# SAMA7G54D2G device description
Architecture: CORTEX-A7; Family: SAMA; Series: SAMA7G
Registers are 32-bit, read-write, reset 0x0 unless marked. A register's access mark holds for its fields unless they carry their own. Offsets are from the block's base; [hi:lo] are bit positions; lines under a group give offsets from that group; {n}, {i} and the like mark numbered series; 'fields as' and 'values as' point back to an identical list.

## I2SMCC — Inter-IC Sound Multi Channel Controller
Instances: I2SMCC0 0xE161C000, I2SMCC1 0xE1620000
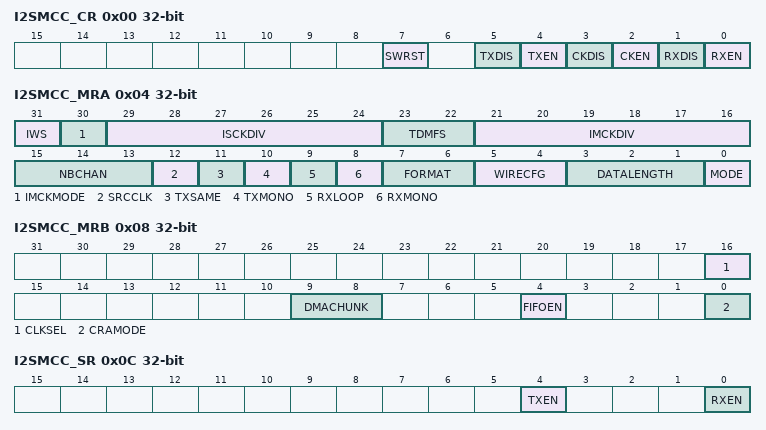
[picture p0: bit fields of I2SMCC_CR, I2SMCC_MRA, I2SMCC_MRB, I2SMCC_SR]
0x00 I2SMCC_CR wo reset not defined — Control Register
  [7] SWRST — Software Reset
    0=No effect; 1=Resets all the registers in the I2SMCC. The I2SMCC is disabled after the reset.
  [5] TXDIS — Transmitter Disable
    0=No effect; 1=Disables the I2SMCC transmitter. Bit I2SMCC_SR.TXEN is cleared when the Transmitter is stopped.
  [4] TXEN — Transmitter Enable
    0=No effect; 1=Enables the I2SMCC transmitter, if TXDIS is not '1'. Bit I2SMCC_SR.TXEN is set when the Transmitter is started.
  [3] CKDIS — Clocks Disable
    0=No effect; 1=Disables the I2SMCC clock generation
  [2] CKEN — Clocks Enable
    0=No effect; 1=Enables the I2SMCC clock generation, if CKDIS is not '1'
  [1] RXDIS — Receiver Disable
    0=No effect; 1=Disables the I2SMCC receiver. Bit I2SMCC_SR.RXEN is cleared when the receiver is stopped.
  [0] RXEN — Receiver Enable
    0=No effect; 1=Enables the I2SMCC receiver, if RXDIS is not '1'. Bit I2SMCC_SR.RXEN is set when the receiver is activated.
0x04 I2SMCC_MRA — Mode Register A
  [31] IWS — I2SMCC_WS Slot Length
    0=I2SMCC_WS slot is 32 bits long for DATALENGTH = 18/20/24 bits; 1=I2SMCC_WS slot is 24 bits long for DATALENGTH = 18/20/24 bits
  [30] IMCKMODE — Master Clock Mode
    0=No master clock generated; 1=Master clock generated
  [29:24] ISCKDIV — Selected Clock to I2SMCC Serial Clock Ratio
  [23:22] TDMFS — TDM Frame Synchronization
    0=SLOT (I2SMCC_WS pulse is high for one time slot at beginning of frame.); 1=HALF (I2SMCC_WS pulse is high for half the time slots at beginning of frame.); 2=BIT (I2SMCC_WS pulse is high for one bit period at beginning of frame, i.e., one ISCK period.)
  [21:16] IMCKDIV — Selected Clock to I2SMCC Master Clock Ratio
  [15:13] NBCHAN — Number of TDM Channels-1
  [12] SRCCLK — Source Clock Selection
    0=The Peripheral clock is selected as source clock; 1=The PMC.GCLKx clock is selected as source clock
  [11] TXSAME — Transmit Data when Underrun
    0='0' is transmitted when underrun; 1=Previous sample transmitted when underrun
  [10] TXMONO — Transmit Mono
    0=Stereo; 1=Mono, with left audio samples duplicated to right audio channel by the I2SMCC
  [9] RXLOOP — Loop-back Test Mode
    0=Normal mode; 1=I2SMCC_DOUT outputs of I2SMCC are internally connected to I2SMCC_DIN inputs
  [8] RXMONO — Receive Mono
    values as TXMONO
  [7:6] FORMAT — Data Format
    0=I2S (I2S format, stereo with I2SMCC_WS low for left channel, and MSB of sample starting one I2SMCC_CK period after I2SMCC_WS edge.); 1=LJ (Left-justified format, stereo with I2SMCC_WS high for left channel, and MSB of sample starting on I2SMCC_WS edge.); 2=TDM (TDM format, with (NBCHAN + 1) channels, I2SMCC_WS high at beginning of first channel, and MSB of sample starting one I2SMCC_CK period after I2SMCC_WS edge.); 3=TDMLJ (TDM format, left-justified, with (NBCHAN + 1) channels, I2SMCC_WS high at beginning of first channel, and MSB of sample starting on I2SMCC_WS edge.)
  [5:4] WIRECFG — Wire Configuration
    0=I2S_1_TDM_0 (In I2S and LJ formats, I2SMCC_DIN0 and I2SMCC_DOUT0 are used to transmit and receive I2S frames. In TDM and TDMLJ formats, I2SMCC_DIN0 and I2SMCC_DOUT0 are used to transmit and receive TDM frames.); 1=I2S_2_TDM_1 (In I2S and LJ formats, I2SMCC_DIN1..0 and I2SMCC_DOUT1..0 are used to transmit and receive 2 I2S frames. In TDM and TDMLJ formats, I2SMCC_DIN1 and I2SMCC_DOUT1 are used to transmit and receive TDM frames.); 2=I2S_4_TDM_2 (In I2S and LJ formats, I2SMCC_DIN3..0 and I2SMCC_DOUT3..0 are used to transmit and receive 4 I2S frames. In TDM and TDMLJ formats, I2SMCC_DIN2 and I2SMCC_DOUT2 are used to transmit and receive TDM frames.); 3=TDM_3 (In I2S and LJ formats, reserved for future use, do not use. In TDM and TDMLJ formats, I2SMCC_DIN3 and I2SMCC_DOUT3 are used to transmit and receive TDM frames.)
  [3:1] DATALENGTH — Data Word Length
    0=32_BITS (Data length is set to 32 bits.); 1=24_BITS (Data length is set to 24 bits.); 2=20_BITS (Data length is set to 20 bits.); 3=18_BITS (Data length is set to 18 bits.); 4=16_BITS (Data length is set to 16 bits.); 5=16_BITS_COMPACT (Data length is set to 16-bit compact stereo. Left sample in bits [15:0] and right sample in bits [31:16] of same word.); 6=8_BITS (Data length is set to 8 bits.); 7=8_BITS_COMPACT (Data length is set to 8-bit compact stereo. Left sample in bits [7:0] and right sample in bits [15:8] of the same word.)
  [0] MODE — Inter-IC Sound Multi Channel Controller Mode
    0=SLAVE (I2SMCC_CK and I2SMCC_WS pin inputs used as bit clock and word select/frame synchronization.); 1=MASTER (Bit clock and word select/frame synchronization generated by I2SMCC from MCK and output to I2SMCC_CK and I2SMCC_WS pins. MCK is output as master clock on I2SMCC_MCK if I2SMCC_MRA.IMCKMODE is set.)
0x08 I2SMCC_MRB — Mode Register B
  [16] CLKSEL — Serial Clock Selection
    0=The I2SMCC_CK clock (provided by the external I2S master) is selected as serial clock; 1=The internal clock (generated from source clock) is selected as serial clock
  [9:8] DMACHUNK — DMA Chunk Size
    0=1_WORD (Each DMA transfer contains 1 word.); 1=2_WORDS (Each DMA transfer contains 2 words.); 2=4_WORDS (Each DMA transfer contains 4 words.); 3=8_WORDS (Each DMA transfer contains 8 words.)
  [4] FIFOEN — FIFO Enable
    0=The Receive and Transmit FIFOs are disabled; 1=The Receive and Transmit FIFOs are enabled. Transmit data can only be written through I2SMCC_THR. Receive data can only be read through I2SMCC_RHR.
  [0] CRAMODE — Common Register Access Mode
    0=LEFT_FIRST (All enabled I2S left channels are filled first, then I2S right channels.); 1=REGULAR (An enabled I2S left channel is filled, then the corresponding right channel, until all channels are filled.)
0x0C I2SMCC_SR ro — Status Register
  [4] TXEN — Transmitter Enabled
    0=Cleared when the transmitter is disabled, following a I2SMCC_CR.TXDIS or I2SMCC_CR.SWRST request; 1=Set when the transmitter is enabled, following a I2SMCC_CR.TXEN request
  [0] RXEN — Receiver Enabled
    0=Cleared when the receiver is disabled, following a RXDIS or SWRST request in I2SMCC_CR; 1=Set when the receiver is enabled, following a RXEN request in I2SMCC_CR
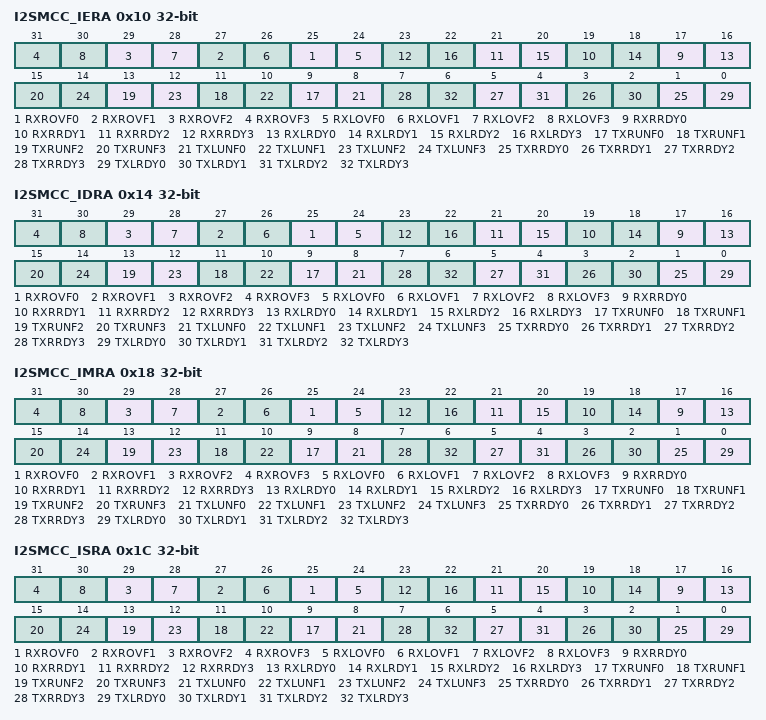
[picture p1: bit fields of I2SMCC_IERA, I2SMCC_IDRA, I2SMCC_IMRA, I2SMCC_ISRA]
0x10 I2SMCC_IERA wo reset not defined (atomic set of I2SMCC_IMRA) — Interrupt Enable Register A
  [2n+25] RXROVF{n} (n=0..3) — I2S Receive Right {n} or TDM Channel [2x]+1 Overrun Interrupt Enable
  [2n+24] RXLOVF{n} (n=0..3) — I2S Receive Left {n} or TDM Channel 2x Overrun Interrupt Enable
  [2n+17] RXRRDY{n} (n=0..3) — I2S Receive Right {n} or TDM Channel [2x]+1 Ready Interrupt Enable
  [2n+16] RXLRDY{n} (n=0..3) — I2S Receive Left {n} or TDM Channel 2x Ready Interrupt Enable
  [2n+9] TXRUNF{n} (n=0..3) — I2S Transmit Right {n} or TDM Channel [2x]+1 Underrun Interrupt Enable
  [2n+8] TXLUNF{n} (n=0..3) — I2S Transmit Left {n} or TDM Channel 2x Underrun Interrupt Enable
  [2n+1] TXRRDY{n} (n=0..3) — I2S Transmit Right {n} or TDM Channel [2x]+1 Ready Interrupt Enable
  [2n] TXLRDY{n} (n=0..3) — I2S Transmit Left {n} or TDM Channel 2x ReadyInterrupt Enable
0x14 I2SMCC_IDRA wo reset not defined (atomic clear of I2SMCC_IMRA) — Interrupt Disable Register A
  [2n+25] RXROVF{n} (n=0..3) — I2S Receive Right {n} or TDM Channel [2x]+1 Overrun Interrupt Disable
  [2n+24] RXLOVF{n} (n=0..3) — I2S Receive Left {n} or TDM Channel 2x Overrun Interrupt Disable
  [2n+17] RXRRDY{n} (n=0..3) — I2S Receive Right {n} or TDM Channel [2x]+1 Ready Interrupt Disable
  [2n+16] RXLRDY{n} (n=0..3) — I2S Receive Left {n} or TDM Channel 2x Ready Interrupt Disable
  [2n+9] TXRUNF{n} (n=0..3) — I2S Transmit Right {n} or TDM Channel [2x]+1 Underrun Interrupt Disable
  [2n+8] TXLUNF{n} (n=0..3) — I2S Transmit Left {n} or TDM Channel 2x Underrun Interrupt Disable
  [2n+1] TXRRDY{n} (n=0..3) — I2S Transmit Right {n} or TDM Channel [2x]+1 Ready Interrupt Disable
  [2n] TXLRDY{n} (n=0..3) — I2S Transmit Left {n} or TDM Channel 2x ReadyInterrupt Disable
0x18 I2SMCC_IMRA ro — Interrupt Mask Register A
  [2n+25] RXROVF{n} (n=0..3) — I2S Receive Right {n} or TDM Channel [2x]+1 Overrun Interrupt Mask
  [2n+24] RXLOVF{n} (n=0..3) — I2S Receive Left {n} or TDM Channel 2x Overrun Interrupt Mask
  [2n+17] RXRRDY{n} (n=0..3) — I2S Receive Right {n} or TDM Channel [2x]+1 Ready Interrupt Mask
  [2n+16] RXLRDY{n} (n=0..3) — I2S Receive Left {n} or TDM Channel 2x Ready Interrupt Mask
  [2n+9] TXRUNF{n} (n=0..3) — I2S Transmit Right {n} or TDM Channel [2x]+1 Underrun Interrupt Mask
  [2n+8] TXLUNF{n} (n=0..3) — I2S Transmit Left {n} or TDM Channel 2x Underrun Interrupt Mask
  [2n+1] TXRRDY{n} (n=0..3) — I2S Transmit Right {n} or TDM Channel [2x]+1 Ready Interrupt Mask
  [2n] TXLRDY{n} (n=0..3) — I2S Transmit Left {n} or TDM Channel 2x ReadyInterrupt Mask
0x1C I2SMCC_ISRA ro — Interrupt Status Register A
  [2n+25] RXROVF{n} (n=0..3) — I2S Receive Right {n} or TDM Channel [2x]+1 Overrun Flag (Cleared on read)
    0=Cleared when I2SMCC_ISRA is read; 1=Set when an overrun error occurs in either I2SMCC_RHRxR or I2SMCC_RHR
  [2n+24] RXLOVF{n} (n=0..3) — I2S Receive Left {n} or TDM Channel 2x Overrun Flag (Cleared on read)
    0=Cleared when I2SMCC_ISRA is read; 1=Set when an overrun error occurs in either I2SMCC_RHLxR or I2SMCC_RHR
  [2n+17] RXRRDY{n} (n=0..3) — I2S Receive Right {n} or TDM Channel [2x]+1 Ready Flag (Cleared by reading I2SMCC_RHR/RHLxR)
    0=Cleared when I2SMCC_RHRxR is read or when the corresponding data has been read through I2SMCC_RHR; 1=Set when received data is available in either I2SMCC_RHRxR or I2SMCC_RHR
  [2n+16] RXLRDY{n} (n=0..3) — I2S Receive Left {n} or TDM Channel 2x Ready Flag (Cleared by reading I2SMCC_RHR/RHLxR)
    0=Cleared when either I2SMCC_RHLxR is read or when the corresponding data has been read in I2SMCC_RHR; 1=Set when received data is available in either I2SMCC_RHLxR or I2SMCC_RHR
  [2n+9] TXRUNF{n} (n=0..3) — I2S Transmit Right {n} or TDM Channel [2x]+1 Underrun Flag (Cleared on read)
    0=Cleared when the I2SMCC_ISRA is read; 1=Set when an underrun error occurs in either I2SMCC_THR or I2SMCC_THRxR
  [2n+8] TXLUNF{n} (n=0..3) — I2S Transmit Left {n} or TDM Channel 2x Underrun (Cleared on read)
    0=Cleared when I2SMCC_ISRA is read; 1=Set when an underrun error occurs in either I2SMCC_THR or I2SMCC_THLxR
  [2n+1] TXRRDY{n} (n=0..3) — I2S Transmit Right {n} or TDM Channel [2x]+1 Ready Flag (Cleared by writing I2SMCC_THR/THRxR)
    0=Cleared when either I2SMCC_THRxR is written or when the corresponding data has been written in I2SMCC_THR; 1=Set when I2SMCC_THR or I2SMCC_THLxR is empty. This status bit is not relevant if I2SMCC_MRB.FIFOEN is set to 1.
  [2n] TXLRDY{n} (n=0..3) — I2S Transmit Left {n} or TDM Channel 2x Ready Flag (Cleared by writing I2SMCC_THR/THLxR)
    0=Cleared when either I2SMCC_THLxR is written or when the corresponding data has been written in I2SMCC_THR; 1=Set when I2SMCC_THR or I2SMCC_THLxR is empty. This status bit is not relevant if I2SMCC_MRB.FIFOEN is set to 1.
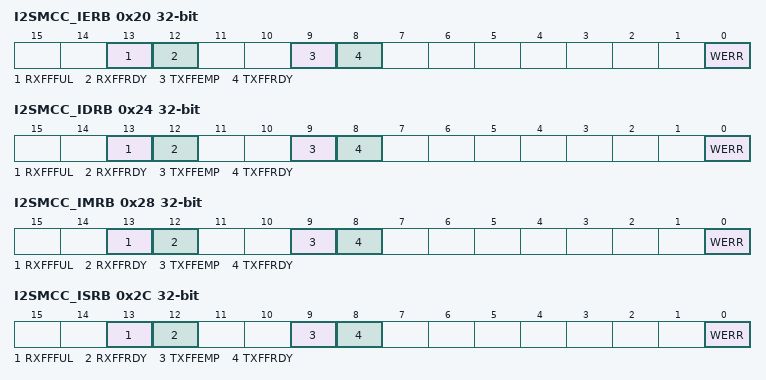
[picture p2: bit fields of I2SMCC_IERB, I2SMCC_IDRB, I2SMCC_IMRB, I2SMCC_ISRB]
0x20 I2SMCC_IERB wo reset not defined (atomic set of I2SMCC_IMRB) — Interrupt Enable Register B
  [13] RXFFFUL — RX FIFO Full Interrupt Enable
  [12] RXFFRDY — RX FIFO Ready Interrupt Enable
  [9] TXFFEMP — TX FIFO Empty Interrupt Enable
  [8] TXFFRDY — TX FIFO Ready Interrupt Enable
  [0] WERR — Write Error Interrupt Enable
0x24 I2SMCC_IDRB wo reset not defined (atomic clear of I2SMCC_IMRB) — Interrupt Disable Register B
  [13] RXFFFUL — RTX FIFO Full Interrupt Disable
  [12] RXFFRDY — RX FIFO Ready Interrupt Disable
  [9] TXFFEMP — TX FIFO Empty Interrupt Disable
  [8] TXFFRDY — TX FIFO Ready Interrupt Disable
  [0] WERR — Write Error Interrupt Disable
0x28 I2SMCC_IMRB ro — Interrupt Mask Register B
  [13] RXFFFUL — RX FIFO Full Interrupt Mask
  [12] RXFFRDY — RX FIFO Ready Interrupt Mask
  [9] TXFFEMP — TX FIFO Empty Interrupt Mask
  [8] TXFFRDY — TX FIFO Ready Interrupt Mask
  [0] WERR — Write Error Interrupt Enable
0x2C I2SMCC_ISRB ro — Interrupt Status Register B
  [13] RXFFFUL — RX FIFO Full Flag (Cleared on read)
    0=Cleared when I2SMCC_ISRB is read; 1=Set when RX FIFO is full. This status bit is not relevant if I2SMCC_MRB.FIFOEN is set to 0.
  [12] RXFFRDY — RX FIFO Ready Flag (Cleared on read)
    0=Cleared when I2SMCC_ISRB is read; 1=Set when RX FIFO is ready to be read. This status bit is not relevant if I2SMCC_MRB.FIFOEN is set to 0.
  [9] TXFFEMP — TX FIFO Empty Flag (Cleared on read)
    0=Cleared when I2SMCC_ISRB is read; 1=Set when TX FIFO is empty. This status bit is not relevant if I2SMCC_MRB.FIFOEN is set to 0.
  [8] TXFFRDY — TX FIFO Ready Flag (Cleared on read)
    0=Cleared when I2SMCC_ISRB is read; 1=Set when TX FIFO is ready to be written. This status bit is not relevant if I2SMCC_MRB.FIFOEN is set to 0.
  [0] WERR — Write Error Flag (cleared on read)
    0=Cleared when I2SMCC_ISRB is read; 1=Set when a write occurs in a protected register
0x30 I2SMCC_RHR ro — Receiver Holding Register
0x34 I2SMCC_THR wo reset not defined — Transmitter Holding Register
{0x40+8i} I2SMCC_RH[{i}] (i=0..3) group
  0x00 I2SMCC_RHLxR ro — Receiver Holding Left x Register
    [31:0] RHL — Receiver Holding Left
  0x04 I2SMCC_RHRxR ro — Receiver Holding Right x Register
    [31:0] RHR — Receiver Holding Right
{0x60+8i} I2SMCC_TH[{i}] (i=0..3) group
  0x00 I2SMCC_THLxR wo reset not defined — Transmitter Holding Left x Register
    [31:0] THL — Transmitter Holding Left
  0x04 I2SMCC_THRxR wo reset not defined — Transmitter Holding Right x Register
    [31:0] THR — Transmitter Holding Right
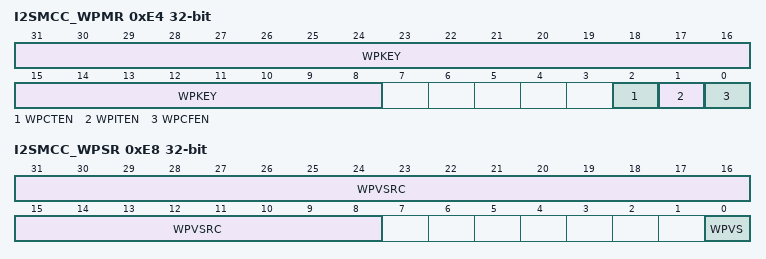
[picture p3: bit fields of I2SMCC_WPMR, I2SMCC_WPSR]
0xE4 I2SMCC_WPMR — Write Protection Mode Register
  [31:8] WPKEY — Write Protection Key
    0x493253=PASSWD (Writing any other value in this field aborts the write operation. Always reads as 0.)
  [2] WPCTEN — Write Protection Control Enable
    0=Disables the write protection of the control if WPKEY matches to 0x493253 (I2S in ASCII); 1=Enables the write protection of the control if WPKEY matches to 0x493253 (I2S in ASCII)
  [1] WPITEN — Write Protection Interrupt Enable
    0=Disables the write protection of the interruption if WPKEY matches to 0x493253 (I2S in ASCII); 1=Enables the write protection of the interruption if WPKEY matches to 0x493253 (I2S in ASCII)
  [0] WPCFEN — Write Protection Configuration Enable
    0=Disables the write protection of the configuration if WPKEY matches to 0x493253 (I2S in ASCII); 1=Enables the write protection of the configuration if WPKEY matches to 0x493253 (I2S in ASCII)
0xE8 I2SMCC_WPSR ro — Write Protection Status Register
  [31:8] WPVSRC — Write Protection Violation Source
  [0] WPVS — Write Protection Violation Status
    0=No write protection violation has occurred since the last read of the I2SMCC_WPSR; 1=A write protection violation has occurred since the last read of the I2SMCC_WPSR. If this violation is an unauthorized attempt to write a protected register, the associated violation is reported into field WPVSRC.

## Notices in the file
Copyright (c) 2020 Microchip Technology Inc.
SPDX-License-Identifier: Apache-2.0
Licensed under the Apache License, Version 2.0 (the "License");
you may not use this file except in compliance with the License.
You may obtain a copy of the License at
http://www.apache.org/licenses/LICENSE-2.0
Unless required by applicable law or agreed to in writing, software
distributed under the License is distributed on an "AS IS" BASIS,
WITHOUT WARRANTIES OR CONDITIONS OF ANY KIND, either express or implied.
See the License for the specific language governing permissions and
limitations under the License.
